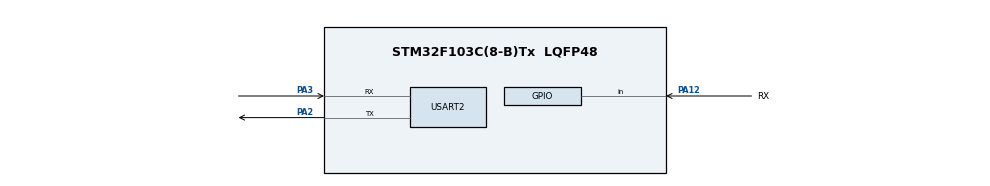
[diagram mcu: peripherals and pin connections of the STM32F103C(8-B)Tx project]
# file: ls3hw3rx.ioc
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Mcu.Family=STM32F1
Mcu.Name=STM32F103C(8-B)Tx
Mcu.Package=LQFP48
NVIC.PriorityGroup=NVIC_PRIORITYGROUP_4
NVIC.USART2_IRQn=true\:0\:0\:false\:false\:true\:true\:true\:true
PA12.GPIO_Label=RX
PA12.GPIO_PuPd=GPIO_PULLUP
PA12.Signal=GPIO_Input
PA13.Mode=Serial_Wire
PA13.Signal=SYS_JTMS-SWDIO
PA14.Mode=Serial_Wire
PA14.Signal=SYS_JTCK-SWCLK
PA2.Mode=Asynchronous
PA2.Signal=USART2_TX
PA3.Mode=Asynchronous
PA3.Signal=USART2_RX
PD0-OSC_IN.Mode=HSE-External-Oscillator
PD0-OSC_IN.Signal=RCC_OSC_IN
PD1-OSC_OUT.Mode=HSE-External-Oscillator
PD1-OSC_OUT.Signal=RCC_OSC_OUT
ProjectManager.HeapSize=0x200
ProjectManager.StackSize=0x400
ProjectManager.TargetToolchain=CMake
RCC.APB1Freq_Value=8000000
RCC.APB2Freq_Value=8000000
USART2.VirtualMode=VM_ASYNC
board=custom

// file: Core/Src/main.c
/* USER CODE BEGIN Header */
/**
  ******************************************************************************
  * @file           : main.c
  * @brief          : Main program body
  ******************************************************************************
  * @attention
  *
  * Copyright (c) 2025 STMicroelectronics.
  * All rights reserved.
  *
  * This software is licensed under terms that can be found in the LICENSE file
  * in the root directory of this software component.
  * If no LICENSE file comes with this software, it is provided AS-IS.
  *
  ******************************************************************************
  */
/* USER CODE END Header */
#include "main.h"

/* USER CODE BEGIN Includes */
#include "stm32f1xx_hal.h"
#include "stm32f1xx_hal_gpio.h"
#include "string.h"
#include "stdio.h"
/* USER CODE END Includes */

UART_HandleTypeDef huart2;

void SystemClock_Config(void);
static void MX_GPIO_Init(void);
static void MX_USART2_UART_Init(void);

/* USER CODE BEGIN 0 */
void Delay_us(uint32_t us)
{
    if (us < 1000) {
        // 对于较短的延时，使用循环计数
        volatile uint32_t count = us * (SystemCoreClock / 1000000) / 5;
        while (count--) {
            __NOP();
        }
    } else {
        // 对于较长的延时，使用HAL_Delay
        HAL_Delay(us / 1000);
        // 处理剩余的微秒部�??
        volatile uint32_t count = (us % 1000) * (SystemCoreClock / 1000000) / 5;
        while (count--) {
            __NOP();
        }
    }
}
uint8_t SoftUART_Rx()
{
    uint32_t bit_time = 104; // ~9600 baud
    uint8_t data = 0;
    uint32_t timeout = 0;
    // 等待起始位下降沿

    while (HAL_GPIO_ReadPin(RX_GPIO_Port, RX_Pin) == GPIO_PIN_SET)
    {
        timeout++;
        if (timeout > 1000000) { // 超时退出
            return 0;
        }
    }
    // 等待1.5个位时间
    Delay_us(bit_time + bit_time/2);

    // 采样 8 个数据位 (LSB first)
    for (int i = 0; i < 8; i++) {
        if (HAL_GPIO_ReadPin(RX_GPIO_Port, RX_Pin)) {
            data |= (1 << i);
        }
        Delay_us(bit_time);
    }

    // 等待停止位结束
    Delay_us(bit_time);

    return data;
}
/* USER CODE END 0 */

int main(void)
{

  /* MCU Configuration--------------------------------------------------------*/

  /* Reset of all peripherals, Initializes the Flash interface and the Systick. */
  HAL_Init();

  /* Configure the system clock */
  SystemClock_Config();

  /* Initialize all configured peripherals */
  MX_GPIO_Init();
  MX_USART2_UART_Init();

  /* Infinite loop */
  /* USER CODE BEGIN WHILE */
  while (1)
  {
  uint8_t received = SoftUART_Rx();
  char buf[20];
   sprintf(buf, "Received: %d\r\n", received);
   HAL_UART_Transmit(&huart2, (uint8_t*)buf, strlen(buf), HAL_MAX_DELAY);
   HAL_Delay(500);

    /* USER CODE END WHILE */

  }
}

void SystemClock_Config(void)
{
  RCC_OscInitTypeDef RCC_OscInitStruct = {0};
  RCC_ClkInitTypeDef RCC_ClkInitStruct = {0};

  /** Initializes the RCC Oscillators according to the specified parameters
  * in the RCC_OscInitTypeDef structure.
  */
  RCC_OscInitStruct.OscillatorType = RCC_OSCILLATORTYPE_HSI;
  RCC_OscInitStruct.HSIState = RCC_HSI_ON;
  RCC_OscInitStruct.HSICalibrationValue = RCC_HSICALIBRATION_DEFAULT;
  RCC_OscInitStruct.PLL.PLLState = RCC_PLL_NONE;
  if (HAL_RCC_OscConfig(&RCC_OscInitStruct) != HAL_OK)
  {
    Error_Handler();
  }

  /** Initializes the CPU, AHB and APB buses clocks
  */
  RCC_ClkInitStruct.ClockType = RCC_CLOCKTYPE_HCLK|RCC_CLOCKTYPE_SYSCLK
                              |RCC_CLOCKTYPE_PCLK1|RCC_CLOCKTYPE_PCLK2;
  RCC_ClkInitStruct.SYSCLKSource = RCC_SYSCLKSOURCE_HSI;
  RCC_ClkInitStruct.AHBCLKDivider = RCC_SYSCLK_DIV1;
  RCC_ClkInitStruct.APB1CLKDivider = RCC_HCLK_DIV1;
  RCC_ClkInitStruct.APB2CLKDivider = RCC_HCLK_DIV1;

  if (HAL_RCC_ClockConfig(&RCC_ClkInitStruct, FLASH_LATENCY_0) != HAL_OK)
  {
    Error_Handler();
  }
}

static void MX_USART2_UART_Init(void)
{

  huart2.Instance = USART2;
  huart2.Init.BaudRate = 115200;
  huart2.Init.WordLength = UART_WORDLENGTH_8B;
  huart2.Init.StopBits = UART_STOPBITS_1;
  huart2.Init.Parity = UART_PARITY_NONE;
  huart2.Init.Mode = UART_MODE_TX_RX;
  huart2.Init.HwFlowCtl = UART_HWCONTROL_NONE;
  huart2.Init.OverSampling = UART_OVERSAMPLING_16;
  if (HAL_UART_Init(&huart2) != HAL_OK)
  {
    Error_Handler();
  }

}

static void MX_GPIO_Init(void)
{
  GPIO_InitTypeDef GPIO_InitStruct = {0};

  /* GPIO Ports Clock Enable */
  __HAL_RCC_GPIOD_CLK_ENABLE();
  __HAL_RCC_GPIOA_CLK_ENABLE();

  /*Configure GPIO pin : RX_Pin */
  GPIO_InitStruct.Pin = RX_Pin;
  GPIO_InitStruct.Mode = GPIO_MODE_INPUT;
  GPIO_InitStruct.Pull = GPIO_PULLUP;
  HAL_GPIO_Init(RX_GPIO_Port, &GPIO_InitStruct);

}

void Error_Handler(void)
{
  __disable_irq();
  while (1)
  {
  }
}
